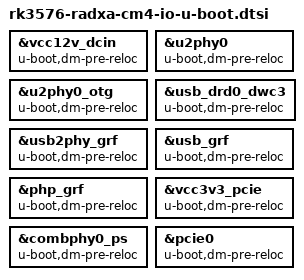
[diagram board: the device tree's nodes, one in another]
// SPDX-License-Identifier: (GPL-2.0+ OR MIT)
/*
 * Copyright (c) 2025 Rockchip Electronics Co., Ltd.
 * Copyright (c) 2025 Radxa Computer (Shenzhen) Co., Ltd.
*/

#include "rk3576-radxa-cm4-u-boot.dtsi"

&vcc12v_dcin {
    u-boot,dm-pre-reloc;
};

/* USB */

&u2phy0 {
	u-boot,dm-pre-reloc;
};

&u2phy0_otg {
	u-boot,dm-pre-reloc;
};

&usb_drd0_dwc3 {
	u-boot,dm-pre-reloc;
};

&usb2phy_grf {
    u-boot,dm-pre-reloc;
};

&usb_grf {
    u-boot,dm-pre-reloc;
};

&php_grf {
    u-boot,dm-pre-reloc;
};

/* PCIe */
&vcc3v3_pcie {
    u-boot,dm-pre-reloc;
};

&combphy0_ps {
    u-boot,dm-pre-reloc;
};

&pcie0 {
    u-boot,dm-pre-reloc;
};
